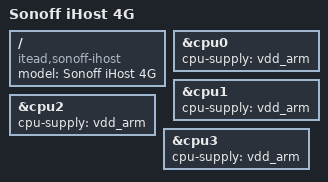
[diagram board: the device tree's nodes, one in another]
// SPDX-License-Identifier: (GPL-2.0+ OR MIT)
/*
 * Copyright (c) 2020 Rockchip Electronics Co., Ltd.
 */

/dts-v1/;
#include "rv1126.dtsi"
#include "rv1126-sonoff-ihost.dtsi"

/ {
	model = "Sonoff iHost 4G";
	compatible = "itead,sonoff-ihost", "rockchip,rv1126";
};

&cpu0 {
	cpu-supply = <&vdd_arm>;
};

&cpu1 {
	cpu-supply = <&vdd_arm>;
};

&cpu2 {
	cpu-supply = <&vdd_arm>;
};

&cpu3 {
	cpu-supply = <&vdd_arm>;
};
